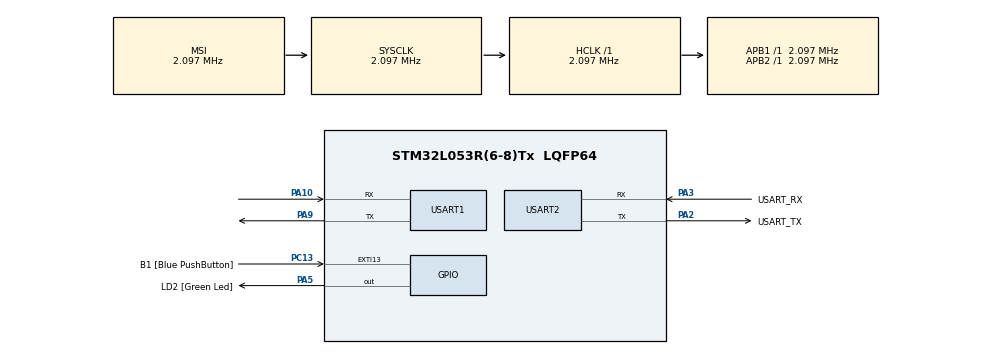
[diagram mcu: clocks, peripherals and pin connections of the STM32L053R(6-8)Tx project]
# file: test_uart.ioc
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Mcu.Family=STM32L0
Mcu.Name=STM32L053R(6-8)Tx
Mcu.Package=LQFP64
PA10.Mode=Asynchronous
PA10.Signal=USART1_RX
PA13.GPIO_Label=TMS
PA13.Mode=Serial_Wire
PA13.Signal=SYS_SWDIO
PA14.GPIO_Label=TCK
PA14.Mode=Serial_Wire
PA14.Signal=SYS_SWCLK
PA2.GPIO_Label=USART_TX
PA2.Mode=Asynchronous
PA2.Signal=USART2_TX
PA3.GPIO_Label=USART_RX
PA3.Mode=Asynchronous
PA3.Signal=USART2_RX
PA5.GPIO_Label=LD2 [Green Led]
PA5.Signal=GPIO_Output
PA9.Mode=Asynchronous
PA9.Signal=USART1_TX
PC13.GPIO_Label=B1 [Blue PushButton]
PC13.GPIO_ModeDefaultEXTI=GPIO_MODE_IT_FALLING
PC13.Signal=GPXTI13
PC14-OSC32_IN.Mode=LSE-External-Oscillator
PC14-OSC32_IN.Signal=RCC_OSC32_IN
PC15-OSC32_OUT.Mode=LSE-External-Oscillator
PC15-OSC32_OUT.Signal=RCC_OSC32_OUT
PH0-OSC_IN.Signal=RCC_OSC_IN
PH1-OSC_OUT.Signal=RCC_OSC_OUT
ProjectManager.HeapSize=0x200
ProjectManager.StackSize=0x400
ProjectManager.TargetToolchain=MDK-ARM V5
RCC.AHBFreq_Value=2097000
RCC.APB1Freq_Value=2097000
RCC.APB1TimFreq_Value=2097000
RCC.APB2Freq_Value=2097000
RCC.APB2TimFreq_Value=2097000
RCC.HSE_VALUE=8000000
RCC.HSI16_VALUE=16000000
RCC.HSI48_VALUE=48000000
RCC.HSI_VALUE=16000000
RCC.MSI_VALUE=2097000
RCC.SYSCLKFreq_VALUE=2097000
RCC.Usart1ClockSelection=RCC_USART1CLKSOURCE_HSI
RCC.Usart2ClockSelection=RCC_USART2CLKSOURCE_HSI
RCC.VCOOutputFreq_Value=48000000
USART1.VirtualMode-Asynchronous=VM_ASYNC
USART1.WordLength=WORDLENGTH_8B
USART2.VirtualMode-Asynchronous=VM_ASYNC
USART2.WordLength=WORDLENGTH_8B
board=NUCLEO-L053R8

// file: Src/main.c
/**
  ******************************************************************************
  * @file           : main.c
  * @brief          : Main program body
  ******************************************************************************
  ** This notice applies to any and all portions of this file
  * that are not between comment pairs USER CODE BEGIN and
  * USER CODE END. Other portions of this file, whether
  * inserted by the user or by software development tools
  * are owned by their respective copyright owners.
  *
  * COPYRIGHT(c) 2018 STMicroelectronics
  *
  * Redistribution and use in source and binary forms, with or without modification,
  * are permitted provided that the following conditions are met:
  *   1. Redistributions of source code must retain the above copyright notice,
  *      this list of conditions and the following disclaimer.
  *   2. Redistributions in binary form must reproduce the above copyright notice,
  *      this list of conditions and the following disclaimer in the documentation
  *      and/or other materials provided with the distribution.
  *   3. Neither the name of STMicroelectronics nor the names of its contributors
  *      may be used to endorse or promote products derived from this software
  *      without specific prior written permission.
  *
  * THIS SOFTWARE IS PROVIDED BY THE COPYRIGHT HOLDERS AND CONTRIBUTORS "AS IS"
  * AND ANY EXPRESS OR IMPLIED WARRANTIES, INCLUDING, BUT NOT LIMITED TO, THE
  * IMPLIED WARRANTIES OF MERCHANTABILITY AND FITNESS FOR A PARTICULAR PURPOSE ARE
  * DISCLAIMED. IN NO EVENT SHALL THE COPYRIGHT HOLDER OR CONTRIBUTORS BE LIABLE
  * FOR ANY DIRECT, INDIRECT, INCIDENTAL, SPECIAL, EXEMPLARY, OR CONSEQUENTIAL
  * DAMAGES (INCLUDING, BUT NOT LIMITED TO, PROCUREMENT OF SUBSTITUTE GOODS OR
  * SERVICES; LOSS OF USE, DATA, OR PROFITS; OR BUSINESS INTERRUPTION) HOWEVER
  * CAUSED AND ON ANY THEORY OF LIABILITY, WHETHER IN CONTRACT, STRICT LIABILITY,
  * OR TORT (INCLUDING NEGLIGENCE OR OTHERWISE) ARISING IN ANY WAY OUT OF THE USE
  * OF THIS SOFTWARE, EVEN IF ADVISED OF THE POSSIBILITY OF SUCH DAMAGE.
  *
  ******************************************************************************
  */
#include "main.h"
#include "stm32l0xx_hal.h"

UART_HandleTypeDef huart1;
UART_HandleTypeDef huart2;

/* USER CODE BEGIN PV */
/* Private variables ---------------------------------------------------------*/
#ifdef __GNUC__
  /* With GCC/RAISONANCE, small printf (option LD Linker->Libraries->Small printf
     set to 'Yes') calls __io_putchar() */
  #define PUTCHAR_PROTOTYPE int __io_putchar(int ch)
#else
  #define PUTCHAR_PROTOTYPE int fputc(int ch, FILE *f)
#endif /* __GNUC__ */

/* USER CODE END PV */

void SystemClock_Config(void);
static void MX_GPIO_Init(void);
static void MX_USART2_UART_Init(void);
static void MX_USART1_UART_Init(void);

/* USER CODE BEGIN PFP */
/* Private function prototypes -----------------------------------------------*/

/* USER CODE END PFP */

int main(void)
{

  /* MCU Configuration----------------------------------------------------------*/

  /* Reset of all peripherals, Initializes the Flash interface and the Systick. */
  HAL_Init();

  /* Configure the system clock */
  SystemClock_Config();

  /* Initialize all configured peripherals */
  MX_GPIO_Init();
  MX_USART2_UART_Init();
  MX_USART1_UART_Init();
  /* USER CODE BEGIN 2 */
  // ch1 = '1';
  ch2 = '2';

  /* USER CODE END 2 */

  /* Infinite loop */
  while (1)
  {

  }

}

void SystemClock_Config(void)
{

  RCC_OscInitTypeDef RCC_OscInitStruct;
  RCC_ClkInitTypeDef RCC_ClkInitStruct;
  RCC_PeriphCLKInitTypeDef PeriphClkInit;

    /**Configure the main internal regulator output voltage
    */
  __HAL_PWR_VOLTAGESCALING_CONFIG(PWR_REGULATOR_VOLTAGE_SCALE1);

    /**Initializes the CPU, AHB and APB busses clocks
    */
  RCC_OscInitStruct.OscillatorType = RCC_OSCILLATORTYPE_HSI|RCC_OSCILLATORTYPE_MSI;
  RCC_OscInitStruct.HSIState = RCC_HSI_ON;
  RCC_OscInitStruct.HSICalibrationValue = 16;
  RCC_OscInitStruct.MSIState = RCC_MSI_ON;
  RCC_OscInitStruct.MSICalibrationValue = 0;
  RCC_OscInitStruct.MSIClockRange = RCC_MSIRANGE_5;
  RCC_OscInitStruct.PLL.PLLState = RCC_PLL_NONE;
  if (HAL_RCC_OscConfig(&RCC_OscInitStruct) != HAL_OK)
  {
    _Error_Handler(__FILE__, __LINE__);
  }

    /**Initializes the CPU, AHB and APB busses clocks
    */
  RCC_ClkInitStruct.ClockType = RCC_CLOCKTYPE_HCLK|RCC_CLOCKTYPE_SYSCLK
                              |RCC_CLOCKTYPE_PCLK1|RCC_CLOCKTYPE_PCLK2;
  RCC_ClkInitStruct.SYSCLKSource = RCC_SYSCLKSOURCE_MSI;
  RCC_ClkInitStruct.AHBCLKDivider = RCC_SYSCLK_DIV1;
  RCC_ClkInitStruct.APB1CLKDivider = RCC_HCLK_DIV1;
  RCC_ClkInitStruct.APB2CLKDivider = RCC_HCLK_DIV1;

  if (HAL_RCC_ClockConfig(&RCC_ClkInitStruct, FLASH_LATENCY_0) != HAL_OK)
  {
    _Error_Handler(__FILE__, __LINE__);
  }

  PeriphClkInit.PeriphClockSelection = RCC_PERIPHCLK_USART1|RCC_PERIPHCLK_USART2;
  PeriphClkInit.Usart1ClockSelection = RCC_USART1CLKSOURCE_HSI;
  PeriphClkInit.Usart2ClockSelection = RCC_USART2CLKSOURCE_HSI;
  if (HAL_RCCEx_PeriphCLKConfig(&PeriphClkInit) != HAL_OK)
  {
    _Error_Handler(__FILE__, __LINE__);
  }

    /**Configure the Systick interrupt time
    */
  HAL_SYSTICK_Config(HAL_RCC_GetHCLKFreq()/1000);

    /**Configure the Systick
    */
  HAL_SYSTICK_CLKSourceConfig(SYSTICK_CLKSOURCE_HCLK);

  /* SysTick_IRQn interrupt configuration */
  HAL_NVIC_SetPriority(SysTick_IRQn, 0, 0);
}

/* USART1 init function */
static void MX_USART1_UART_Init(void)
{

  huart1.Instance = USART1;
  huart1.Init.BaudRate = 115200;
  huart1.Init.WordLength = UART_WORDLENGTH_8B;
  huart1.Init.StopBits = UART_STOPBITS_1;
  huart1.Init.Parity = UART_PARITY_NONE;
  huart1.Init.Mode = UART_MODE_TX_RX;
  huart1.Init.HwFlowCtl = UART_HWCONTROL_NONE;
  huart1.Init.OverSampling = UART_OVERSAMPLING_16;
  huart1.Init.OneBitSampling = UART_ONE_BIT_SAMPLE_DISABLE;
  huart1.AdvancedInit.AdvFeatureInit = UART_ADVFEATURE_NO_INIT;
  if (HAL_UART_Init(&huart1) != HAL_OK)
  {
    _Error_Handler(__FILE__, __LINE__);
  }

}

/* USART2 init function */
static void MX_USART2_UART_Init(void)
{

  huart2.Instance = USART2;
  huart2.Init.BaudRate = 115200;
  huart2.Init.WordLength = UART_WORDLENGTH_8B;
  huart2.Init.StopBits = UART_STOPBITS_1;
  huart2.Init.Parity = UART_PARITY_NONE;
  huart2.Init.Mode = UART_MODE_TX_RX;
  huart2.Init.HwFlowCtl = UART_HWCONTROL_NONE;
  huart2.Init.OverSampling = UART_OVERSAMPLING_16;
  huart2.Init.OneBitSampling = UART_ONE_BIT_SAMPLE_DISABLE;
  huart2.AdvancedInit.AdvFeatureInit = UART_ADVFEATURE_NO_INIT;
  if (HAL_UART_Init(&huart2) != HAL_OK)
  {
    _Error_Handler(__FILE__, __LINE__);
  }

}

/** Configure pins as
        * Analog
        * Input
        * Output
        * EVENT_OUT
        * EXTI
*/
static void MX_GPIO_Init(void)
{

  GPIO_InitTypeDef GPIO_InitStruct;

  /* GPIO Ports Clock Enable */
  __HAL_RCC_GPIOC_CLK_ENABLE();
  __HAL_RCC_GPIOH_CLK_ENABLE();
  __HAL_RCC_GPIOA_CLK_ENABLE();

  /*Configure GPIO pin Output Level */
  HAL_GPIO_WritePin(LD2_GPIO_Port, LD2_Pin, GPIO_PIN_RESET);

  /*Configure GPIO pin : B1_Pin */
  GPIO_InitStruct.Pin = B1_Pin;
  GPIO_InitStruct.Mode = GPIO_MODE_IT_FALLING;
  GPIO_InitStruct.Pull = GPIO_NOPULL;
  HAL_GPIO_Init(B1_GPIO_Port, &GPIO_InitStruct);

  /*Configure GPIO pin : LD2_Pin */
  GPIO_InitStruct.Pin = LD2_Pin;
  GPIO_InitStruct.Mode = GPIO_MODE_OUTPUT_PP;
  GPIO_InitStruct.Pull = GPIO_NOPULL;
  GPIO_InitStruct.Speed = GPIO_SPEED_FREQ_LOW;
  HAL_GPIO_Init(LD2_GPIO_Port, &GPIO_InitStruct);

}

/* USER CODE BEGIN 4 */
PUTCHAR_PROTOTYPE
{  /* Place your implementation of fputc here */

  HAL_UART_Transmit(&huart2, (uint8_t *)&ch, 1, 0xFFFF);
  /* e.g. write a character to the USART */
  // USART_SendData(EVAL_COM1, (uint8_t) ch);

  // /* Loop until the end of transmission */
  // while (USART_GetFlagStatus(EVAL_COM1, USART_FLAG_TC) == RESET)
  // {}

  return ch;
}
/* USER CODE END 4 */

void _Error_Handler(char *file, int line)
{
  while(1)
  {
  }
}

/************************ (C) COPYRIGHT STMicroelectronics *****END OF FILE****/
